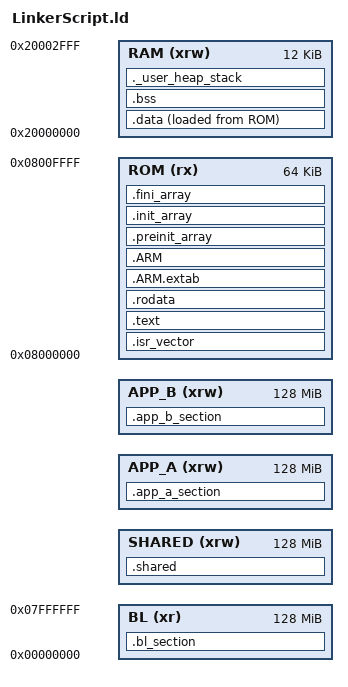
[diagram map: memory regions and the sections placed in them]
/*
******************************************************************************
**
**  File        : LinkerScript.ld
**
**  Author		: Auto-generated by Ac6 System Workbench
**
**  Abstract    : Linker script for STM32F303R8Tx Device from STM32F30 series
**                12Kbytes RAM
**                64Kbytes ROM
**
**                Set heap size, stack size and stack location according
**                to application requirements.
**
**                Set memory bank area and size if external memory is used.
**
**  Target      : STMicroelectronics STM32
**
**  Distribution: The file is distributed �as is,� without any warranty
**                of any kind.
**
*****************************************************************************
** @attention
**
** <h2><center>&copy; COPYRIGHT(c) 2017 Ac6</center></h2>
**
** Redistribution and use in source and binary forms, with or without modification,
** are permitted provided that the following conditions are met:
**   1. Redistributions of source code must retain the above copyright notice,
**      this list of conditions and the following disclaimer.
**   2. Redistributions in binary form must reproduce the above copyright notice,
**      this list of conditions and the following disclaimer in the documentation
**      and/or other materials provided with the distribution.
**   3. Neither the name of Ac6 nor the names of its contributors
**      may be used to endorse or promote products derived from this software
**      without specific prior written permission.
**
** THIS SOFTWARE IS PROVIDED BY THE COPYRIGHT HOLDERS AND CONTRIBUTORS "AS IS"
** AND ANY EXPRESS OR IMPLIED WARRANTIES, INCLUDING, BUT NOT LIMITED TO, THE
** IMPLIED WARRANTIES OF MERCHANTABILITY AND FITNESS FOR A PARTICULAR PURPOSE ARE
** DISCLAIMED. IN NO EVENT SHALL THE COPYRIGHT HOLDER OR CONTRIBUTORS BE LIABLE
** FOR ANY DIRECT, INDIRECT, INCIDENTAL, SPECIAL, EXEMPLARY, OR CONSEQUENTIAL
** DAMAGES (INCLUDING, BUT NOT LIMITED TO, PROCUREMENT OF SUBSTITUTE GOODS OR
** SERVICES; LOSS OF USE, DATA, OR PROFITS; OR BUSINESS INTERRUPTION) HOWEVER
** CAUSED AND ON ANY THEORY OF LIABILITY, WHETHER IN CONTRACT, STRICT LIABILITY,
** OR TORT (INCLUDING NEGLIGENCE OR OTHERWISE) ARISING IN ANY WAY OUT OF THE USE
** OF THIS SOFTWARE, EVEN IF ADVISED OF THE POSSIBILITY OF SUCH DAMAGE.
**
*****************************************************************************
*/


/* Entry Point */
ENTRY(Reset_Handler)

/*Code space is .5GB, we need four sections
 * 0 is bootloader
 * 1 is shared
 * 2 is AppA
 * 3 is AppB 
 
 * Total size is 0x20000000, so divide by 4, size per section
  is 0x8000000 */

SECTION_LENGTH = 0x8000000;

BL_ORIGIN = 0x0;
SHARED_ORIGIN = (BL_ORIGIN + SECTION_LENGTH);
APPA_ORIGIN = (SHARED_ORIGIN + SECTION_LENGTH);
APPB_ORIGIN = (APPA_ORIGIN + SECTION_LENGTH);

/* Highest address of the user mode stack */
_estack = 0x20003000;    /* end of RAM */

_Min_Heap_Size = 0;      /* required amount of heap  */
_Min_Stack_Size = 0x400; /* required amount of stack */

/* Memories definition */
MEMORY
{
  RAM (xrw)		: ORIGIN = 0x20000000, LENGTH = 12K
  ROM (rx)		: ORIGIN = 0x8000000, LENGTH = 64K
  BL (xr)		: ORIGIN = BL_ORIGIN, LENGTH = SECTION_LENGTH
  SHARED (xrw)		: ORIGIN = SHARED_ORIGIN, LENGTH = SECTION_LENGTH
  APP_A (xrw)		: ORIGIN = APPA_ORIGIN, LENGTH = SECTION_LENGTH
  APP_B (xrw)		: ORIGIN = APPB_ORIGIN, LENGTH = SECTION_LENGTH
}

/* Sections */
SECTIONS
{
  /* The startup code into ROM memory */
  .isr_vector :
  {
    . = ALIGN(4);
    KEEP(*(.isr_vector)) /* Startup code */
    . = ALIGN(4);
  } >ROM

  .bl_section :
  {
    . = ALIGN(4);
    __bl_section_start__ = .;
    *(.bl_section*)    
    *main.o (.text .text*)
    __bl_section_end__ = .;  
  *(EXCLUDE_FILE(*main.o) .text .text*) /*exclude the main.o from the .text section to prevent multiple definition error.*/
  } > BL

  /*  .shared: 0x1000*/
  .shared : 
  {
    KEEP(*(.shared))
  } >SHARED

  .app_a_section :
  {
    . = ALIGN(4);
    __app_a_section_start__ = .;
    *(.app_a_section*)    
    *main.o (.text .text*)
    __app_a_section_end__ = .;  
  *(EXCLUDE_FILE(*main_A.o) .text .text*) /*exclude the main.o from the .text section to prevent multiple definition error.*/
  } > APP_A

  .app_b_section :
  {
    . = ALIGN(4);
    __app_b_section_start__ = .;
    *(.app_b_section*)    
    *main.o (.text .text*)
    __app_b_section_end__ = .;  
  *(EXCLUDE_FILE(*main_B.o) .text .text*) /*exclude the main.o from the .text section to prevent multiple definition error.*/
  } > APP_B

  /* The program code and other data into ROM memory */
  .text :
  {
    . = ALIGN(4);
    *(.text)           /* .text sections (code) */
    *(.text*)          /* .text* sections (code) */
    *(.glue_7)         /* glue arm to thumb code */
    *(.glue_7t)        /* glue thumb to arm code */
    *(.eh_frame)

    KEEP (*(.init))
    KEEP (*(.fini))

    . = ALIGN(4);
    _etext = .;        /* define a global symbols at end of code */
  } >ROM

  /* Constant data into ROM memory*/
  .rodata :
  {
    . = ALIGN(4);
    *(.rodata)         /* .rodata sections (constants, strings, etc.) */
    *(.rodata*)        /* .rodata* sections (constants, strings, etc.) */
    . = ALIGN(4);
  } >ROM

  .ARM.extab   : { 
  	. = ALIGN(4);
  	*(.ARM.extab* .gnu.linkonce.armextab.*)
  	. = ALIGN(4);
  } >ROM
  
  .ARM : {
    . = ALIGN(4);
    __exidx_start = .;
    *(.ARM.exidx*)
    __exidx_end = .;
    . = ALIGN(4);
  } >ROM

  .preinit_array     :
  {
    . = ALIGN(4);
    PROVIDE_HIDDEN (__preinit_array_start = .);
    KEEP (*(.preinit_array*))
    PROVIDE_HIDDEN (__preinit_array_end = .);
    . = ALIGN(4);
  } >ROM
  
  .init_array :
  {
    . = ALIGN(4);
    PROVIDE_HIDDEN (__init_array_start = .);
    KEEP (*(SORT(.init_array.*)))
    KEEP (*(.init_array*))
    PROVIDE_HIDDEN (__init_array_end = .);
    . = ALIGN(4);
  } >ROM
  
  .fini_array :
  {
    . = ALIGN(4);
    PROVIDE_HIDDEN (__fini_array_start = .);
    KEEP (*(SORT(.fini_array.*)))
    KEEP (*(.fini_array*))
    PROVIDE_HIDDEN (__fini_array_end = .);
    . = ALIGN(4);
  } >ROM

  /* Used by the startup to initialize data */
  _sidata = LOADADDR(.data);

  /* Initialized data sections into RAM memory */
  .data : 
  {
    . = ALIGN(4);
    _sdata = .;        /* create a global symbol at data start */
    *(.data)           /* .data sections */
    *(.data*)          /* .data* sections */

    . = ALIGN(4);
    _edata = .;        /* define a global symbol at data end */
  } >RAM AT> ROM

  
  /* Uninitialized data section into RAM memory */
  . = ALIGN(4);
  .bss :
  {
    /* This is used by the startup in order to initialize the .bss secion */
    _sbss = .;         /* define a global symbol at bss start */
    __bss_start__ = _sbss;
    *(.bss)
    *(.bss*)
    *(COMMON)

    . = ALIGN(4);
    _ebss = .;         /* define a global symbol at bss end */
    __bss_end__ = _ebss;
  } >RAM

  /* User_heap_stack section, used to check that there is enough RAM left */
  ._user_heap_stack :
  {
    . = ALIGN(8);
    PROVIDE ( end = . );
    PROVIDE ( _end = . );
    . = . + _Min_Heap_Size;
    . = . + _Min_Stack_Size;
    . = ALIGN(8);
  } >RAM

  

  /* Remove information from the compiler libraries */
  /DISCARD/ :
  {
    libc.a ( * )
    libm.a ( * )
    libgcc.a ( * )
  }

  .ARM.attributes 0 : { *(.ARM.attributes) }
}
